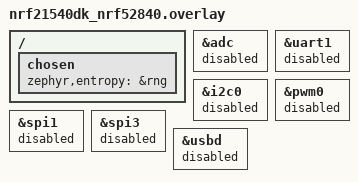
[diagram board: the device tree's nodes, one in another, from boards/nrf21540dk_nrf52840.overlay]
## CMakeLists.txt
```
#
# Copyright (c) 2021 Nordic Semiconductor ASA
#
# SPDX-License-Identifier: LicenseRef-Nordic-5-Clause
#

cmake_minimum_required(VERSION 3.20.0)

find_package(Zephyr REQUIRED HINTS $ENV{ZEPHYR_BASE})
project(matter-lock)

# Enable GNU STD support and initialize the Matter Data Model.
include(${ZEPHYR_CONNECTEDHOMEIP_MODULE_DIR}/config/nrfconnect/app/enable-gnu-std.cmake)
include(${ZEPHYR_CONNECTEDHOMEIP_MODULE_DIR}/src/app/chip_data_model.cmake)

# NORDIC SDK APP START

# Include all source files that are located in the Matter common directory.
include(${ZEPHYR_NRF_MODULE_DIR}/samples/matter/common/cmake/source_common.cmake)

target_include_directories(app PRIVATE
    src
    ${CONFIG_NCS_SAMPLE_MATTER_ZAP_FILES_PATH}
)

SET(access_srcs src/access/access_data_types.cpp
              src/access/access_manager_credentials.cpp
              src/access/access_manager_users.cpp
              src/access/access_manager.cpp
              src/access/access_storage.cpp
              )

if(CONFIG_LOCK_SCHEDULES)
    LIST(APPEND access_srcs src/access/access_manager_schedules.cpp)
endif()

target_sources(app PRIVATE
    src/app_task.cpp
    src/bolt_lock_manager.cpp
    src/main.cpp
    src/zcl_callbacks.cpp
    ${access_srcs}
)

if(CONFIG_THREAD_WIFI_SWITCHING)
    target_sources(app PRIVATE
        src/thread_wifi_switch.cpp
    )
endif()

chip_configure_data_model(app
    INCLUDE_SERVER
    BYPASS_IDL
    GEN_DIR ${CONFIG_NCS_SAMPLE_MATTER_ZAP_FILES_PATH}/zap-generated
    ZAP_FILE ${CMAKE_CURRENT_SOURCE_DIR}/${CONFIG_NCS_SAMPLE_MATTER_ZAP_FILES_PATH}/lock.zap
)
# NORDIC SDK APP END
```

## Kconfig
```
#
# Copyright (c) 2021 Nordic Semiconductor
#
# SPDX-License-Identifier: LicenseRef-Nordic-5-Clause
#

mainmenu "Matter Lock sample application"

config LOCK_MAX_NUM_USERS
	int "Maximum number of users supported by the lock"
	default 10

config LOCK_MAX_NUM_CREDENTIALS_PER_USER
	int "Maximum total number of credentials per one user supported by the lock"
	default 4

config LOCK_MAX_NUM_CREDENTIALS_PER_TYPE
	int "Maximum number of credentials of given type supported by the lock"
	default 15

config LOCK_MAX_CREDENTIAL_LENGTH
	int "Maximum length of the single credential supported by the lock"
	default 10

config LOCK_SCHEDULES
	bool "Support for WeekDay, YearDay and Holiday schedules in lock"
	help
	  This option adds support for an optional Timed Schedule Access Lock feature.
	  You can use Week Day, Year Day and Holiday schedules to restrict access for a
	  specific user for a defined time window. For example, use it to
	  give the user access only for three days in week.

if LOCK_SCHEDULES

config LOCK_MAX_WEEKDAY_SCHEDULES_PER_USER
	int "Maximum number of WeekDay schedules per one user supported by the lock"
	default 5

config LOCK_MAX_YEARDAY_SCHEDULES_PER_USER
	int "Maximum number of YearDay schedules per one user supported by the lock"
	default 5

config LOCK_MAX_HOLIDAY_SCHEDULES
	int "Maximum number of Holiday schedules supported by the lock"
	default 5

endif

config LOCK_ENABLE_DEBUG
	bool "Enable debug features to print users and credentials"
	depends on SHELL
	help
	  Debug features allows to checking and printing current users, their state, and
	  associated credentials. Use these with shell commands combinations to read saved credentials
	  or users, and manage them (add, clear, read).

if LOCK_ENABLE_DEBUG

config LOCK_PRINT_STORAGE_STATUS
	bool "Print storage status after each store call"
	help
	  Debug feature to print the debug-level log that contains information of the entry being stored
	  to persistent storage and how many bytes are left to store the new entry. It can be used to verify
	  whether credential, schedule or user entries are written properly to persistent storage.
	  This option should be disabled in production firmware
	  version.

# This should be deterined based on the maximum possible command length that depends on the LOCK_MAX_CREDENTIAL_LENGTH
config SHELL_CMD_BUFF_SIZE
	default 300

endif

config LOCK_LEAVE_FABRIC_CLEAR_CREDENTIAL
	bool "Clear all credentials assigned to given fabric index"
	default y
	help
	  This feature allows to remove all credentials which were created or modified
	  within the fabric which is being removed from the door lock.

config STATE_LEDS
	bool "Use LEDs to indicate the device state"
	default y
	help
	  Use LEDs to render the current state of the device such as the progress of commissioning of
	  the device into a network or the factory reset initiation. Note that setting this option to
	  'n' does not disable the LED indicating the state of the simulated bolt.

config THREAD_WIFI_SWITCHING
	bool "Switching between Thread and Wi-Fi"
	depends on SOC_SERIES_NRF53X
	depends on NET_L2_OPENTHREAD
	depends on CHIP_WIFI
	depends on !CHIP_FACTORY_RESET_ERASE_SETTINGS
	select EXPERIMENTAL
	help
	  Build the application with both Thread and Wi-Fi support and initialize
	  either transport based on the current configuration. A user can switch
	  between Thread and Wi-Fi by pressing and holding Button 3 for more than
	  10 seconds. During the switching, the device is automatically factory
	  reset and rebooted.

if THREAD_WIFI_SWITCHING

config THREAD_WIFI_SWITCHING_SHELL
	bool "Shell command for switching between Thread and Wi-Fi"
	default y if SHELL
	help
	  Add "switch_transport" shell command that initiates switching between
	  Thread and Wi-Fi transport for Matter protocol stack.

endif # THREAD_WIFI_SWITCHING

# Sample configuration used for Thread networking
if NET_L2_OPENTHREAD

choice OPENTHREAD_NORDIC_LIBRARY_CONFIGURATION
	default OPENTHREAD_NORDIC_LIBRARY_MTD
endchoice

choice OPENTHREAD_DEVICE_TYPE
	default OPENTHREAD_MTD
endchoice

config CHIP_ENABLE_ICD_SUPPORT
	default y

# Reduce Thread TX output power to 0 dBm for SED device
config OPENTHREAD_DEFAULT_TX_POWER
	int
	default 0

endif # NET_L2_OPENTHREAD

if CHIP_WIFI

config NRF_WIFI_LOW_POWER
	default y

endif # CHIP_WIFI

config NCS_SAMPLE_MATTER_PERSISTENT_STORAGE
	default y

# PSA SSF Crypto Client is not ready for the secure storage backend
if !PSA_SSF_CRYPTO_CLIENT

config NCS_SAMPLE_MATTER_SECURE_STORAGE_BACKEND
	default y if !CHIP_WIFI

config NCS_SAMPLE_MATTER_SETTINGS_STORAGE_BACKEND
	default n if !CHIP_WIFI

endif

# Increase the storage capacity if the schedules are enabled with secure storage
# This also implies increasing of the OT and Matter stacks because some operations
# performed during commissioning seem to allocate stack buffers based on the
# maximum possible secure asset size.
if LOCK_SCHEDULES && NCS_SAMPLE_MATTER_SECURE_STORAGE_BACKEND

config NCS_SAMPLE_MATTER_SECURE_STORAGE_MAX_ENTRY_NUMBER
	default 128

config TRUSTED_STORAGE_BACKEND_AEAD_MAX_DATA_SIZE
	default 3072

config OPENTHREAD_THREAD_STACK_SIZE
	default 5120

config CHIP_TASK_STACK_SIZE
	default 9216

endif

source "${ZEPHYR_CONNECTEDHOMEIP_MODULE_DIR}/config/nrfconnect/chip-module/Kconfig.features"
source "${ZEPHYR_CONNECTEDHOMEIP_MODULE_DIR}/config/nrfconnect/chip-module/Kconfig.defaults"
source "${ZEPHYR_NRF_MODULE_DIR}/samples/matter/common/src/Kconfig"
source "Kconfig.zephyr"
```

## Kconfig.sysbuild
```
#
# Copyright (c) 2023 Nordic Semiconductor ASA
#
# SPDX-License-Identifier: LicenseRef-Nordic-5-Clause
#

config WIFI_NRF70
	default y if BOARD_NRF7002DK

#### Radio core selection
config NRF_DEFAULT_IPC_RADIO
	default y

# Enable IEEE802.15.4 serialization to network core
# This config automatically pulls in the `overlay-802154.conf` in the ipc_radio image
config NETCORE_IPC_RADIO_IEEE802154
	default y if (SOC_SERIES_NRF53X || SOC_SERIES_NRF54HX) && !WIFI_NRF70

# Enable Bluetooth serialization to network core
# This config automatically pulls in the `overlay-bt_hci_ipc.conf` in the ipc_radio image
config NETCORE_IPC_RADIO_BT_HCI_IPC
	default y if (SOC_SERIES_NRF53X || SOC_SERIES_NRF54HX)

#### Bootloader
choice BOOTLOADER
	default BOOTLOADER_MCUBOOT if !BOARD_NRF21540DK && !SOC_SERIES_NRF54HX
endchoice

if BOOTLOADER_MCUBOOT

#### DFU multi-image support
config DFU_MULTI_IMAGE_PACKAGE_BUILD
	default y

config DFU_MULTI_IMAGE_PACKAGE_APP
	default y

config PM_EXTERNAL_FLASH_MCUBOOT_SECONDARY
	default y

#### DFU network core configuration
if SOC_SERIES_NRF53X

config MCUBOOT_UPDATEABLE_IMAGES
	default 2

choice MCUBOOT_MODE
	default MCUBOOT_MODE_OVERWRITE_ONLY
endchoice

choice BOOT_SIGNATURE_TYPE
	default BOOT_SIGNATURE_TYPE_RSA
endchoice

config SECURE_BOOT_NETCORE
	default y

config NETCORE_APP_UPDATE
	default y

config DFU_MULTI_IMAGE_PACKAGE_NET
	default y

endif # SOC_SERIES_NRF53X

if BOARD_NRF54L15DK_NRF54L15_CPUAPP_NS

# Disable checking the external drivers for NS build.
config PM_OVERRIDE_EXTERNAL_DRIVER_CHECK
	default y

# override the mcuboot pad size, because it is not set globally for NS build.
config PM_MCUBOOT_PAD
	default 0x800

endif # BOARD_NRF54L15DK_NRF54L15_CPUAPP_NS

endif # BOOTLOADER_MCUBOOT

if SOC_SERIES_NRF54HX

config SUIT_ENVELOPE
	default y

config SUIT_BUILD_FLASH_COMPANION
	default y

config SUIT_MULTI_IMAGE_PACKAGE_BUILD
	default y if MATTER_OTA

endif # SOC_SERIES_NRF54HX

#### Enable generating factory data
config MATTER_FACTORY_DATA_GENERATE
	default y if !BOARD_NRF21540DK

source "${ZEPHYR_BASE}/share/sysbuild/Kconfig"
```

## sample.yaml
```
sample:
  description: Matter Lock example
  name: Matter Lock
tests:
  sample.matter.lock.debug:
    sysbuild: true
    build_only: true
    integration_platforms:
      - nrf52840dk/nrf52840
      - nrf5340dk/nrf5340/cpuapp
      - nrf7002dk/nrf5340/cpuapp
      - nrf7002dk/nrf5340/cpuapp/nrf7001
      - nrf54l15dk/nrf54l15/cpuapp
      - nrf54l15dk/nrf54l15/cpuapp/ns
      - nrf54h20dk/nrf54h20/cpuapp
    platform_allow: nrf52840dk/nrf52840 nrf5340dk/nrf5340/cpuapp nrf7002dk/nrf5340/cpuapp
      nrf7002dk/nrf5340/cpuapp/nrf7001 nrf54l15dk/nrf54l15/cpuapp
      nrf54h20dk/nrf54h20/cpuapp nrf54l15dk/nrf54l15/cpuapp/ns
    tags: sysbuild ci_samples_matter
  sample.matter.lock.release:
    sysbuild: true
    build_only: true
    extra_args: FILE_SUFFIX=release
    integration_platforms:
      - nrf52840dk/nrf52840
      - nrf5340dk/nrf5340/cpuapp
      - nrf7002dk/nrf5340/cpuapp
      - nrf7002dk/nrf5340/cpuapp/nrf7001
      - nrf54l15dk/nrf54l15/cpuapp
      - nrf54h20dk/nrf54h20/cpuapp
    platform_allow: nrf52840dk/nrf52840 nrf5340dk/nrf5340/cpuapp nrf7002dk/nrf5340/cpuapp
      nrf7002dk/nrf5340/cpuapp/nrf7001 nrf54l15dk/nrf54l15/cpuapp
      nrf54h20dk/nrf54h20/cpuapp
    tags: sysbuild ci_samples_matter
  sample.matter.lock.lto:
    sysbuild: true
    build_only: true
    extra_args: CONFIG_LTO=y CONFIG_ISR_TABLES_LOCAL_DECLARATION=y
    integration_platforms:
      - nrf52840dk/nrf52840
      - nrf5340dk/nrf5340/cpuapp
      - nrf7002dk/nrf5340/cpuapp
      - nrf7002dk/nrf5340/cpuapp/nrf7001
      - nrf54l15dk/nrf54l15/cpuapp
    platform_allow: nrf52840dk/nrf52840 nrf5340dk/nrf5340/cpuapp nrf7002dk/nrf5340/cpuapp
      nrf7002dk/nrf5340/cpuapp/nrf7001 nrf54l15dk/nrf54l15/cpuapp
    tags: sysbuild ci_samples_matter
  sample.matter.lock.smp_dfu:
    sysbuild: true
    build_only: true
    extra_args: CONFIG_CHIP_DFU_OVER_BT_SMP=y
    integration_platforms:
      - nrf52840dk/nrf52840
      - nrf5340dk/nrf5340/cpuapp
      - nrf7002dk/nrf5340/cpuapp
      - nrf7002dk/nrf5340/cpuapp/nrf7001
      - nrf54l15dk/nrf54l15/cpuapp
    platform_allow: nrf52840dk/nrf52840 nrf5340dk/nrf5340/cpuapp nrf7002dk/nrf5340/cpuapp
      nrf7002dk/nrf5340/cpuapp/nrf7001 nrf54l15dk/nrf54l15/cpuapp
    tags: sysbuild ci_samples_matter
  sample.matter.lock.no_dfu.no_fd:
    sysbuild: true
    build_only: true
    extra_args: SB_CONFIG_MATTER_OTA=n
    integration_platforms:
      - nrf21540dk/nrf52840
    platform_allow: nrf21540dk/nrf52840
    tags: sysbuild ci_samples_matter
  sample.matter.lock.thread_wifi_switched.lto.smp_dfu:
    sysbuild: true
    build_only: true
    extra_args: lock_SHIELD=nrf7002ek
      FILE_SUFFIX=thread_wifi_switched SB_CONFIG_WIFI_PATCHES_EXT_FLASH_STORE=y
      SB_CONFIG_MCUBOOT_UPDATEABLE_IMAGES=3 CONFIG_CHIP_DFU_OVER_BT_SMP=y
      SB_CONFIG_WIFI_NRF70=y SB_CONFIG_DFU_MULTI_IMAGE_PACKAGE_WIFI_FW_PATCH=y
    integration_platforms:
      - nrf5340dk/nrf5340/cpuapp
    platform_allow: nrf5340dk/nrf5340/cpuapp
    tags: sysbuild ci_samples_matter
  sample.matter.lock.nus:
    sysbuild: true
    build_only: true
    extra_args: CONFIG_CHIP_NUS=y CONFIG_BT_FIXED_PASSKEY=y CONFIG_CHIP_NUS_FIXED_PASSKEY=112233
    integration_platforms:
      - nrf52840dk/nrf52840
      - nrf5340dk/nrf5340/cpuapp
    platform_allow: nrf52840dk/nrf52840 nrf5340dk/nrf5340/cpuapp nrf54l15dk/nrf54l15/cpuapp
    tags: sysbuild ci_samples_matter
  sample.matter.lock.release.nrf54l15.power_consumption:
    sysbuild: true
    build_only: true
    extra_args: FILE_SUFFIX=release CONFIG_NCS_SAMPLE_MATTER_LEDS=n
      CONFIG_CHIP_ENABLE_PAIRING_AUTOSTART=y CONFIG_NCS_SAMPLE_MATTER_WATCHDOG=n
    integration_platforms:
      - nrf54l15dk/nrf54l15/cpuapp
    platform_allow: nrf54l15dk/nrf54l15/cpuapp
    tags: sysbuild ci_samples_matter
```

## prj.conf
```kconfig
#
# Copyright (c) 2022 Nordic Semiconductor ASA
#
# SPDX-License-Identifier: LicenseRef-Nordic-5-Clause
#

# This sample uses Kconfig.defaults to set options common for all
# samples. This file should contain only options specific for this sample
# or overrides of default values.

# Enable CHIP
CONFIG_CHIP=y
CONFIG_CHIP_PROJECT_CONFIG="src/chip_project_config.h"
# 32774 == 0x8006 (example lock-app)
CONFIG_CHIP_DEVICE_PRODUCT_ID=32774
CONFIG_STD_CPP17=y

# Enable Matter extended announcement and increase duration to 1 hour.
CONFIG_CHIP_BLE_EXT_ADVERTISING=y
CONFIG_CHIP_BLE_ADVERTISING_DURATION=60

# Add support for LEDs and buttons on Nordic development kits
CONFIG_DK_LIBRARY=y

# Bluetooth Low Energy configuration
CONFIG_BT_DEVICE_NAME="MatterLock"

# Suspend devices when the CPU goes into sleep
CONFIG_PM_DEVICE=y

# Other settings
CONFIG_THREAD_NAME=y
CONFIG_MPU_STACK_GUARD=y
CONFIG_RESET_ON_FATAL_ERROR=n
CONFIG_CHIP_LIB_SHELL=y
CONFIG_NCS_SAMPLE_MATTER_TEST_SHELL=y

# Reduce application size
CONFIG_USE_SEGGER_RTT=n
CONFIG_MATTER_LOG_LEVEL_INF=y
CONFIG_CHIP_APP_LOG_LEVEL=3

# Enable Factory Data feature
CONFIG_CHIP_FACTORY_DATA=y
CONFIG_CHIP_FACTORY_DATA_BUILD=y
```

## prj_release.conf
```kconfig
#
# Copyright (c) 2022 Nordic Semiconductor ASA
#
# SPDX-License-Identifier: LicenseRef-Nordic-5-Clause
#

# This sample uses Kconfig.defaults to set options common for all
# samples. This file should contain only options specific for this sample
# or overrides of default values.

# Enable CHIP
CONFIG_CHIP=y
CONFIG_CHIP_PROJECT_CONFIG="src/chip_project_config.h"
# 32774 == 0x8006 (example lock-app)
CONFIG_CHIP_DEVICE_PRODUCT_ID=32774
CONFIG_STD_CPP17=y

# Enable Matter extended announcement and increase duration to 1 hour.
CONFIG_CHIP_BLE_EXT_ADVERTISING=y
CONFIG_CHIP_BLE_ADVERTISING_DURATION=60

# Add support for LEDs and buttons on Nordic development kits
CONFIG_DK_LIBRARY=y

# Bluetooth Low Energy configuration
CONFIG_BT_DEVICE_NAME="MatterLock"

# Suspend devices when the CPU goes into sleep
CONFIG_PM_DEVICE=y

# Enable system reset on fatal error
CONFIG_RESET_ON_FATAL_ERROR=y

# Try to disable unused RAM blocks to reduce power consumption
CONFIG_RAM_POWER_DOWN_LIBRARY=y

# Disable all debug features
CONFIG_USE_SEGGER_RTT=n
CONFIG_SHELL=n
CONFIG_OPENTHREAD_SHELL=n
CONFIG_CONSOLE=n
CONFIG_UART_CONSOLE=n
CONFIG_SERIAL=n
CONFIG_LOG=n
CONFIG_LOG_MODE_MINIMAL=n
CONFIG_ASSERT_VERBOSE=n
CONFIG_ASSERT_NO_FILE_INFO=y
CONFIG_PRINTK=n
CONFIG_PRINTK_SYNC=n
CONFIG_THREAD_NAME=n
CONFIG_BOOT_BANNER=n

# Enable Factory Data feature
CONFIG_CHIP_FACTORY_DATA=y
CONFIG_CHIP_FACTORY_DATA_BUILD=y

# Enable Watchdog
CONFIG_NCS_SAMPLE_MATTER_WATCHDOG=y
```

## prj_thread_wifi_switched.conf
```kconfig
#
# Copyright (c) 2022 Nordic Semiconductor ASA
#
# SPDX-License-Identifier: LicenseRef-Nordic-5-Clause
#

# This sample uses Kconfig.defaults to set options common for all
# samples. This file should contain only options specific for this sample
# or overrides of default values.

# Enable CHIP
CONFIG_CHIP=y
CONFIG_CHIP_PROJECT_CONFIG="src/chip_project_config.h"
# 32774 == 0x8006 (example lock-app)
CONFIG_CHIP_DEVICE_PRODUCT_ID=32774
CONFIG_STD_CPP17=y

# Enable Matter extended announcement and increase duration to 1 hour.
CONFIG_CHIP_BLE_EXT_ADVERTISING=y
CONFIG_CHIP_BLE_ADVERTISING_DURATION=60

# Add support for LEDs and buttons on Nordic development kits
CONFIG_DK_LIBRARY=y

# Bluetooth Low Energy configuration
CONFIG_BT_DEVICE_NAME="MatterLock"

# Other settings
CONFIG_MPU_STACK_GUARD=y
CONFIG_RESET_ON_FATAL_ERROR=n

# Enable switching between Thread and Wi-Fi variants
CONFIG_THREAD_WIFI_SWITCHING=y
CONFIG_THREAD_WIFI_SWITCHING_SHELL=y
CONFIG_CHIP_WIFI=y
CONFIG_NET_L2_OPENTHREAD=y
CONFIG_CHIP_FACTORY_RESET_ERASE_SETTINGS=n # Do not restore initial transport on factory reset

# Reduce application size
CONFIG_USE_SEGGER_RTT=n
CONFIG_WIFI_NM_WPA_SUPPLICANT_ADVANCED_FEATURES=n
CONFIG_CHIP_NFC_COMMISSIONING=n
CONFIG_MATTER_LOG_LEVEL_INF=y
CONFIG_CHIP_APP_LOG_LEVEL=3
CONFIG_THREAD_NAME=n
CONFIG_BOOT_BANNER=n

# Enable Factory Data feature
CONFIG_CHIP_FACTORY_DATA=y
CONFIG_CHIP_FACTORY_DATA_BUILD=y

# Enable LTO
CONFIG_LTO=y
CONFIG_ISR_TABLES_LOCAL_DECLARATION=y

# Enforce the use of mbedTLS crypto backend instead of PSA Crypto by
# building OpenThread from sources. Wi-Fi stack does not support PSA Crypto yet.
CONFIG_OPENTHREAD_SOURCES=y

# Do not enable RAM power-down library for nRF7002 DK due to incompatible WiFi configuration.
CONFIG_RAM_POWER_DOWN_LIBRARY=n
```

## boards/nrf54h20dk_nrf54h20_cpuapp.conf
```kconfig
#
# Copyright (c) 2024 Nordic Semiconductor ASA
#
# SPDX-License-Identifier: LicenseRef-Nordic-5-Clause
#

# Disable Oberon PSA crypto drivers
CONFIG_PSA_CRYPTO_DRIVER_OBERON=n

# Enable PSA crypto from SSF client
CONFIG_PSA_SSF_CRYPTO_CLIENT=y
CONFIG_SSF_PSA_CRYPTO_SERVICE_ENABLED=y

# Disable Data Cache
CONFIG_DCACHE=n

# Enable cache processing for application core.
# It will add the application firmware to the cache partition.
CONFIG_SUIT_DFU_CACHE_EXTRACT_IMAGE=y

# Set the ZMS sector count to match the settings partition size that is 32 kB for this application.
CONFIG_SETTINGS_ZMS_SECTOR_COUNT=8
# Workaround required as Zephyr L2 implies usage of NVS backend for settings.
# It should be removed once the proper fix will be applied in Zephyr.
CONFIG_NVS=n

# TODO: Enable factory data once it is available
CONFIG_CHIP_FACTORY_DATA=n
CONFIG_CHIP_CRYPTO_PSA_MIGRATE_DAC_PRIV_KEY=n

# TODO: Workaround to be removed once Zephyr's CONFIG_FPROTECT is supported on nRF54H20.
CONFIG_CHIP_FACTORY_DATA_WRITE_PROTECT=n

# Disable GPD
CONFIG_SOC_NRF54H20_GPD=n
```

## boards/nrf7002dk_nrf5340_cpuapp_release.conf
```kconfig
#
# Copyright (c) 2024 Nordic Semiconductor ASA
#
# SPDX-License-Identifier: LicenseRef-Nordic-5-Clause
#

# Do not enable RAM power-down library for nRF7002 DK due to incompatible WiFi configuration.
CONFIG_RAM_POWER_DOWN_LIBRARY=n

# Enable LTO to decrease the flash usage.
CONFIG_LTO=y
CONFIG_ISR_TABLES_LOCAL_DECLARATION=y
```

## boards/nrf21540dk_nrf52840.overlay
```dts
/* Copyright (c) 2021 Nordic Semiconductor ASA
 *
 * SPDX-License-Identifier: LicenseRef-Nordic-5-Clause
 */

/ {
	/*
	* In some default configurations within the nRF Connect SDK,
	* e.g. on nRF52840, the chosen zephyr,entropy node is &cryptocell.
	* This devicetree overlay ensures that default is overridden wherever it
	* is set, as this application uses the RNG node for entropy exclusively.
	*/
	chosen {
		zephyr,entropy = &rng;
	};
};

/* Disable unused peripherals to reduce power consumption */
&adc {
	status = "disabled";
};
&uart1 {
	status = "disabled";
};
&i2c0 {
	status = "disabled";
};
&pwm0 {
	status = "disabled";
};
&spi1 {
	status = "disabled";
};
&spi3 {
	status = "disabled";
};
&usbd {
	status = "disabled";
};
```

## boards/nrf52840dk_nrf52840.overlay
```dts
/* Copyright (c) 2021 Nordic Semiconductor ASA
 *
 * SPDX-License-Identifier: LicenseRef-Nordic-5-Clause
 */

/ {
	chosen {
		nordic,pm-ext-flash = &mx25r64;
	};

	/*
	* In some default configurations within the nRF Connect SDK,
	* e.g. on nRF52840, the chosen zephyr,entropy node is &cryptocell.
	* This devicetree overlay ensures that default is overridden wherever it
	* is set, as this application uses the RNG node for entropy exclusively.
	*/
	chosen {
		zephyr,entropy = &rng;
	};
};

/* Disable unused peripherals to reduce power consumption */
&adc {
	status = "disabled";
};
&uart1 {
	status = "disabled";
};
&i2c0 {
	status = "disabled";
};
&pwm0 {
	status = "disabled";
};
&spi1 {
	status = "disabled";
};
&spi3 {
	status = "disabled";
};
&usbd {
	status = "disabled";
};
```

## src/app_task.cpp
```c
/*
 * Copyright (c) 2021 Nordic Semiconductor ASA
 *
 * SPDX-License-Identifier: LicenseRef-Nordic-5-Clause
 */

#include "app_task.h"

#include "bolt_lock_manager.h"

#ifdef CONFIG_THREAD_WIFI_SWITCHING
#include "thread_wifi_switch.h"
#endif

#include "app/matter_init.h"
#include "app/task_executor.h"

#ifdef CONFIG_CHIP_NUS
#include "bt_nus/bt_nus_service.h"
#endif

#ifdef CONFIG_CHIP_OTA_REQUESTOR
#include "dfu/ota/ota_util.h"
#endif

#include <app-common/zap-generated/attributes/Accessors.h>
#include <app/clusters/door-lock-server/door-lock-server.h>
#include <app/clusters/identify-server/identify-server.h>
#include <app/server/OnboardingCodesUtil.h>
#include <platform/CHIPDeviceLayer.h>

#include <zephyr/logging/log.h>

LOG_MODULE_DECLARE(app, CONFIG_CHIP_APP_LOG_LEVEL);

using namespace ::chip;
using namespace ::chip::app;
using namespace ::chip::DeviceLayer;

namespace
{
constexpr EndpointId kLockEndpointId = 1;

#ifdef CONFIG_CHIP_NUS
constexpr uint16_t kAdvertisingIntervalMin = 400;
constexpr uint16_t kAdvertisingIntervalMax = 500;
constexpr uint8_t kLockNUSPriority = 2;
#endif

#ifdef CONFIG_THREAD_WIFI_SWITCHING
k_timer sSwitchTransportTimer;
constexpr uint32_t kSwitchTransportTimeout = 10000;
#endif

#define APPLICATION_BUTTON_MASK DK_BTN2_MSK
#define SWITCHING_BUTTON_MASK DK_BTN3_MSK
} /* namespace */

Identify sIdentify = { kLockEndpointId, AppTask::IdentifyStartHandler, AppTask::IdentifyStopHandler,
		       Clusters::Identify::IdentifyTypeEnum::kVisibleIndicator };

void AppTask::IdentifyStartHandler(Identify *)
{
	Nrf::PostTask(
		[] { Nrf::GetBoard().GetLED(Nrf::DeviceLeds::LED2).Blink(Nrf::LedConsts::kIdentifyBlinkRate_ms); });
}

void AppTask::IdentifyStopHandler(Identify *)
{
	Nrf::PostTask([] { Nrf::GetBoard().GetLED(Nrf::DeviceLeds::LED2).Set(BoltLockMgr().IsLocked()); });
}

void AppTask::ButtonEventHandler(Nrf::ButtonState state, Nrf::ButtonMask hasChanged)
{
	if ((APPLICATION_BUTTON_MASK & hasChanged) & state) {
		Nrf::PostTask([] { LockActionEventHandler(); });
	}

#ifdef CONFIG_THREAD_WIFI_SWITCHING
	if (SWITCHING_BUTTON_MASK & hasChanged) {
		SwitchButtonAction action =
			(SWITCHING_BUTTON_MASK & state) ? SwitchButtonAction::Pressed : SwitchButtonAction::Released;
		Nrf::PostTask([action] { SwitchTransportTriggerHandler(action); });
	}
#endif
}

void AppTask::LockActionEventHandler()
{
	if (BoltLockMgr().IsLocked()) {
		BoltLockMgr().Unlock(BoltLockManager::OperationSource::kButton);
	} else {
		BoltLockMgr().Lock(BoltLockManager::OperationSource::kButton);
	}
}

#ifdef CONFIG_THREAD_WIFI_SWITCHING
void AppTask::SwitchTransportEventHandler()
{
	LOG_INF("Switching to %s", ThreadWifiSwitch::IsThreadActive() ? "Wi-Fi" : "Thread");

	ThreadWifiSwitch::SwitchTransport();
}

void AppTask::SwitchTransportTimerTimeoutCallback(k_timer *timer)
{
	Nrf::PostTask([] { SwitchTransportEventHandler(); });
}

void AppTask::SwitchTransportTriggerHandler(const SwitchButtonAction &action)
{
	if (action == SwitchButtonAction::Pressed) {
		LOG_INF("Keep button pressed for %u ms to switch to %s", kSwitchTransportTimeout,
			ThreadWifiSwitch::IsThreadActive() ? "Wi-Fi" : "Thread");
		k_timer_start(&sSwitchTransportTimer, K_MSEC(kSwitchTransportTimeout), K_NO_WAIT);
	} else {
		LOG_INF("Switching to %s cancelled", ThreadWifiSwitch::IsThreadActive() ? "Wi-Fi" : "Thread");
		k_timer_stop(&sSwitchTransportTimer);
	}
}
#endif

void AppTask::LockStateChanged(BoltLockManager::State state, BoltLockManager::OperationSource source)
{
	switch (state) {
	case BoltLockManager::State::kLockingInitiated:
		LOG_INF("Lock action initiated");
		Nrf::GetBoard().GetLED(Nrf::DeviceLeds::LED2).Blink(50, 50);
#ifdef CONFIG_CHIP_NUS
		Nrf::GetNUSService().SendData("locking", sizeof("locking"));
#endif
		break;
	case BoltLockManager::State::kLockingCompleted:
		LOG_INF("Lock action completed");
		Nrf::GetBoard().GetLED(Nrf::DeviceLeds::LED2).Set(true);
#ifdef CONFIG_CHIP_NUS
		Nrf::GetNUSService().SendData("locked", sizeof("locked"));
#endif
		break;
	case BoltLockManager::State::kUnlockingInitiated:
		LOG_INF("Unlock action initiated");
		Nrf::GetBoard().GetLED(Nrf::DeviceLeds::LED2).Blink(50, 50);
#ifdef CONFIG_CHIP_NUS
		Nrf::GetNUSService().SendData("unlocking", sizeof("unlocking"));
#endif
		break;
	case BoltLockManager::State::kUnlockingCompleted:
		LOG_INF("Unlock action completed");
#ifdef CONFIG_CHIP_NUS
		Nrf::GetNUSService().SendData("unlocked", sizeof("unlocked"));
#endif
		Nrf::GetBoard().GetLED(Nrf::DeviceLeds::LED2).Set(false);
		break;
	}

	/* Handle changing attribute state in the application */
	Instance().UpdateClusterState(state, source);
}

void AppTask::UpdateClusterState(BoltLockManager::State state, BoltLockManager::OperationSource source)
{
	DlLockState newLockState;

	switch (state) {
	case BoltLockManager::State::kLockingCompleted:
		newLockState = DlLockState::kLocked;
		break;
	case BoltLockManager::State::kUnlockingCompleted:
		newLockState = DlLockState::kUnlocked;
		break;
	default:
		newLockState = DlLockState::kNotFullyLocked;
		break;
	}

	SystemLayer().ScheduleLambda([newLockState, source] {
		chip::app::DataModel::Nullable<chip::app::Clusters::DoorLock::DlLockState> currentLockState;
		chip::app::Clusters::DoorLock::Attributes::LockState::Get(kLockEndpointId, currentLockState);

		if (currentLockState.IsNull()) {
			/* Initialize lock state with start value, but not invoke lock/unlock. */
			chip::app::Clusters::DoorLock::Attributes::LockState::Set(kLockEndpointId, newLockState);
		} else {
			LOG_INF("Updating LockState attribute");

			if (!DoorLockServer::Instance().SetLockState(kLockEndpointId, newLockState, source)) {
				LOG_ERR("Failed to update LockState attribute");
			}
		}
	});
}

#ifdef CONFIG_CHIP_NUS
void AppTask::NUSLockCallback(void *context)
{
	LOG_DBG("Received LOCK command from NUS");
	if (BoltLockMgr().mState == BoltLockManager::State::kLockingCompleted ||
	    BoltLockMgr().mState == BoltLockManager::State::kLockingInitiated) {
		LOG_INF("Device is already locked");
	} else {
		Nrf::PostTask([] { LockActionEventHandler(); });
	}
}

void AppTask::NUSUnlockCallback(void *context)
{
	LOG_DBG("Received UNLOCK command from NUS");
	if (BoltLockMgr().mState == BoltLockManager::State::kUnlockingCompleted ||
	    BoltLockMgr().mState == BoltLockManager::State::kUnlockingInitiated) {
		LOG_INF("Device is already unlocked");
	} else {
		Nrf::PostTask([] { LockActionEventHandler(); });
	}
}
#endif

#ifdef CONFIG_NCS_SAMPLE_MATTER_TEST_EVENT_TRIGGERS
CHIP_ERROR AppTask::DoorLockJammedEventCallback(Nrf::Matter::TestEventTrigger::TriggerValue)
{
	VerifyOrReturnError(DoorLockServer::Instance().SendLockAlarmEvent(kLockEndpointId, AlarmCodeEnum::kLockJammed),
			    CHIP_ERROR_INTERNAL);
	LOG_ERR("Event Trigger: Doorlock jammed.");
	return CHIP_NO_ERROR;
}
#endif

CHIP_ERROR AppTask::Init()
{
	/* Initialize Matter stack */
#ifdef CONFIG_THREAD_WIFI_SWITCHING
	/* In the Thread/Wi-Fi switchable mode, it is the ThreadWifiSwitch module that owns the NetworkCommissioning
	   instances, so offload the initialization module from controlling that by explicitly setting the
	   mNetworkingInstance parameter to nullptr. Otherwise, the initialization module instantiates the
	   NetworkCommissioning object and handles it by default internally. */
	ReturnErrorOnFailure(Nrf::Matter::PrepareServer(Nrf::Matter::InitData{ .mNetworkingInstance = nullptr }));
#else
	ReturnErrorOnFailure(Nrf::Matter::PrepareServer());
#endif

	if (!Nrf::GetBoard().Init(ButtonEventHandler)) {
		LOG_ERR("User interface initialization failed.");
		return CHIP_ERROR_INCORRECT_STATE;
	}

	/* Register Matter event handler that controls the connectivity status LED based on the captured Matter network
	 * state. */
	ReturnErrorOnFailure(Nrf::Matter::RegisterEventHandler(Nrf::Board::DefaultMatterEventHandler, 0));

#ifdef CONFIG_THREAD_WIFI_SWITCHING
	CHIP_ERROR err = ThreadWifiSwitch::StartCurrentTransport();
	if (err != CHIP_NO_ERROR) {
		LOG_ERR("ThreadWifiSwitch::StartCurrentTransport() failed: %" CHIP_ERROR_FORMAT, err.Format());
		return err;
	}

	k_timer_init(&sSwitchTransportTimer, &AppTask::SwitchTransportTimerTimeoutCallback, nullptr);
#endif

#ifdef CONFIG_CHIP_NUS
	/* Initialize Nordic UART Service for Lock purposes */
	if (!Nrf::GetNUSService().Init(kLockNUSPriority, kAdvertisingIntervalMin, kAdvertisingIntervalMax)) {
		ChipLogError(Zcl, "Cannot initialize NUS service");
	}
	Nrf::GetNUSService().RegisterCommand("Lock", sizeof("Lock"), NUSLockCallback, nullptr);
	Nrf::GetNUSService().RegisterCommand("Unlock", sizeof("Unlock"), NUSUnlockCallback, nullptr);
	if (!Nrf::GetNUSService().StartServer()) {
		LOG_ERR("GetNUSService().StartServer() failed");
	}
#endif

	/* Initialize lock manager */
	BoltLockMgr().Init(LockStateChanged);

	/* Register Door Lock test event trigger */
#ifdef CONFIG_NCS_SAMPLE_MATTER_TEST_EVENT_TRIGGERS
	ReturnErrorOnFailure(Nrf::Matter::TestEventTrigger::Instance().RegisterTestEventTrigger(
		kDoorLockJammedEventTriggerId,
		Nrf::Matter::TestEventTrigger::EventTrigger{ 0, DoorLockJammedEventCallback }));
#endif

	return Nrf::Matter::StartServer();
}

CHIP_ERROR AppTask::StartApp()
{
	ReturnErrorOnFailure(Init());

	while (true) {
		Nrf::DispatchNextTask();
	}

	return CHIP_NO_ERROR;
}
```

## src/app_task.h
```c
/*
 * Copyright (c) 2021 Nordic Semiconductor ASA
 *
 * SPDX-License-Identifier: LicenseRef-Nordic-5-Clause
 */

#pragma once

#include "board/board.h"
#include "board/led_widget.h"
#include "bolt_lock_manager.h"

struct k_timer;
struct Identify;

#ifdef CONFIG_THREAD_WIFI_SWITCHING
enum class SwitchButtonAction : uint8_t { Pressed, Released };
#endif

#ifdef CONFIG_NCS_SAMPLE_MATTER_TEST_EVENT_TRIGGERS
#include "event_triggers/event_triggers.h"
#endif

class AppTask {
public:
	static AppTask &Instance()
	{
		static AppTask sAppTask;
		return sAppTask;
	};

	CHIP_ERROR StartApp();

	void UpdateClusterState(BoltLockManager::State state, BoltLockManager::OperationSource source);
	static void IdentifyStartHandler(Identify *);
	static void IdentifyStopHandler(Identify *);

private:
	CHIP_ERROR Init();

	static void LockActionEventHandler();
	static void ButtonEventHandler(Nrf::ButtonState state, Nrf::ButtonMask hasChanged);
	static void LockStateChanged(BoltLockManager::State state, BoltLockManager::OperationSource source);

#ifdef CONFIG_THREAD_WIFI_SWITCHING
	static void SwitchTransportEventHandler();
	static void SwitchTransportTimerTimeoutCallback(k_timer *timer);
	static void SwitchTransportTriggerHandler(const SwitchButtonAction &action);
#endif

#ifdef CONFIG_CHIP_NUS
	static void NUSLockCallback(void *context);
	static void NUSUnlockCallback(void *context);
#endif

#ifdef CONFIG_NCS_SAMPLE_MATTER_TEST_EVENT_TRIGGERS
	constexpr static Nrf::Matter::TestEventTrigger::EventTriggerId kDoorLockJammedEventTriggerId = 0xFFFF'FFFF'3277'4000;
	static CHIP_ERROR DoorLockJammedEventCallback(Nrf::Matter::TestEventTrigger::TriggerValue);
#endif
};
```

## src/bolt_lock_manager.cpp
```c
/*
 * Copyright (c) 2021 Nordic Semiconductor ASA
 *
 * SPDX-License-Identifier: LicenseRef-Nordic-5-Clause
 */

#include "bolt_lock_manager.h"
#include "app/task_executor.h"

#include "app_task.h"

using namespace chip;

BoltLockManager BoltLockManager::sLock;

void BoltLockManager::Init(StateChangeCallback callback)
{
	mStateChangeCallback = callback;

	k_timer_init(&mActuatorTimer, &BoltLockManager::ActuatorTimerEventHandler, nullptr);
	k_timer_user_data_set(&mActuatorTimer, this);

	AccessMgr::Instance().Init();

	/* Set the default state */
	Nrf::GetBoard().GetLED(Nrf::DeviceLeds::LED2).Set(IsLocked());
}

bool BoltLockManager::GetUser(uint16_t userIndex, EmberAfPluginDoorLockUserInfo &user)
{
	return AccessMgr::Instance().GetUserInfo(userIndex, user);
}

bool BoltLockManager::SetUser(uint16_t userIndex, FabricIndex creator, FabricIndex modifier, const CharSpan &userName,
			      uint32_t uniqueId, UserStatusEnum userStatus, UserTypeEnum userType,
			      CredentialRuleEnum credentialRule, const CredentialStruct *credentials,
			      size_t totalCredentials)
{
	return AccessMgr::Instance().SetUser(userIndex, creator, modifier, userName, uniqueId, userStatus, userType,
					      credentialRule, credentials, totalCredentials);
}

bool BoltLockManager::GetCredential(uint16_t credentialIndex, CredentialTypeEnum credentialType,
				    EmberAfPluginDoorLockCredentialInfo &credential)
{
	return AccessMgr::Instance().GetCredential(credentialIndex, credentialType, credential);
}

bool BoltLockManager::SetCredential(uint16_t credentialIndex, FabricIndex creator, FabricIndex modifier,
				    DlCredentialStatus credentialStatus, CredentialTypeEnum credentialType,
				    const ByteSpan &secret)
{
	return AccessMgr::Instance().SetCredential(credentialIndex, creator, modifier, credentialStatus,
						    credentialType, secret);
}

#ifdef CONFIG_LOCK_SCHEDULES

DlStatus BoltLockManager::GetWeekDaySchedule(uint8_t weekdayIndex, uint16_t userIndex,
					     EmberAfPluginDoorLockWeekDaySchedule &schedule)
{
	return AccessMgr::Instance().GetWeekDaySchedule(weekdayIndex, userIndex, schedule);
}

DlStatus BoltLockManager::SetWeekDaySchedule(uint8_t weekdayIndex, uint16_t userIndex, DlScheduleStatus status,
					     DaysMaskMap daysMask, uint8_t startHour, uint8_t startMinute,
					     uint8_t endHour, uint8_t endMinute)
{
	return AccessMgr::Instance().SetWeekDaySchedule(weekdayIndex, userIndex, status, daysMask, startHour,
							 startMinute, endHour, endMinute);
}

DlStatus BoltLockManager::GetYearDaySchedule(uint8_t yearDayIndex, uint16_t userIndex,
					     EmberAfPluginDoorLockYearDaySchedule &schedule)
{
	return AccessMgr::Instance().GetYearDaySchedule(yearDayIndex, userIndex, schedule);
}

DlStatus BoltLockManager::SetYearDaySchedule(uint8_t yeardayIndex, uint16_t userIndex, DlScheduleStatus status,
					     uint32_t localStartTime, uint32_t localEndTime)
{
	return AccessMgr::Instance().SetYearDaySchedule(yeardayIndex, userIndex, status, localStartTime, localEndTime);
}

DlStatus BoltLockManager::GetHolidaySchedule(uint8_t holidayIndex, EmberAfPluginDoorLockHolidaySchedule &schedule)
{
	return AccessMgr::Instance().GetHolidaySchedule(holidayIndex, schedule);
}

DlStatus BoltLockManager::SetHolidaySchedule(uint8_t holidayIndex, DlScheduleStatus status, uint32_t localStartTime,
					     uint32_t localEndTime, OperatingModeEnum operatingMode)
{
	return AccessMgr::Instance().SetHolidaySchedule(holidayIndex, status, localStartTime, localEndTime,
							 operatingMode);
}

#endif /* CONFIG_LOCK_SCHEDULES */


bool BoltLockManager::ValidatePIN(const Optional<ByteSpan> &pinCode, OperationErrorEnum &err)
{
	return AccessMgr::Instance().ValidatePIN(pinCode, err);
}

void BoltLockManager::SetRequirePIN(bool require)
{
	return AccessMgr::Instance().SetRequirePIN(require);
}
bool BoltLockManager::GetRequirePIN()
{
	return AccessMgr::Instance().GetRequirePIN();
}

void BoltLockManager::Lock(OperationSource source)
{
	VerifyOrReturn(mState != State::kLockingCompleted);
	SetState(State::kLockingInitiated, source);

	mActuatorOperationSource = source;
	k_timer_start(&mActuatorTimer, K_MSEC(kActuatorMovementTimeMs), K_NO_WAIT);
}

void BoltLockManager::Unlock(OperationSource source)
{
	VerifyOrReturn(mState != State::kUnlockingCompleted);
	SetState(State::kUnlockingInitiated, source);

	mActuatorOperationSource = source;
	k_timer_start(&mActuatorTimer, K_MSEC(kActuatorMovementTimeMs), K_NO_WAIT);
}

void BoltLockManager::ActuatorTimerEventHandler(k_timer *timer)
{
	/*
	 * The timer event handler is called in the context of the system clock ISR.
	 * Post an event to the application task queue to process the event in the
	 * context of the application thread.
	 */

	BoltLockManagerEvent event;
	event.manager = static_cast<BoltLockManager *>(k_timer_user_data_get(timer));
	Nrf::PostTask([event] { ActuatorAppEventHandler(event); });
}

void BoltLockManager::ActuatorAppEventHandler(const BoltLockManagerEvent &event)
{
	BoltLockManager *lock = reinterpret_cast<BoltLockManager *>(event.manager);

	switch (lock->mState) {
	case State::kLockingInitiated:
		lock->SetState(State::kLockingCompleted, lock->mActuatorOperationSource);
		break;
	case State::kUnlockingInitiated:
		lock->SetState(State::kUnlockingCompleted, lock->mActuatorOperationSource);
		break;
	default:
		break;
	}
}

void BoltLockManager::SetState(State state, OperationSource source)
{
	mState = state;

	if (mStateChangeCallback != nullptr) {
		mStateChangeCallback(state, source);
	}
}
```

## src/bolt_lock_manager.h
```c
/*
 * Copyright (c) 2021 Nordic Semiconductor ASA
 *
 * SPDX-License-Identifier: LicenseRef-Nordic-5-Clause
 */

#pragma once

#include "access/access_manager.h"

#include <app/clusters/door-lock-server/door-lock-server.h>
#include <lib/core/ClusterEnums.h>

#include <zephyr/kernel.h>

#include <cstdint>

struct BoltLockManagerEvent;

class BoltLockManager {
public:
	static constexpr size_t kMaxCredentialLength = 128;

	enum class State : uint8_t {
		kLockingInitiated = 0,
		kLockingCompleted,
		kUnlockingInitiated,
		kUnlockingCompleted,
	};

	struct UserData {
		char mName[DOOR_LOCK_USER_NAME_BUFFER_SIZE];
		CredentialStruct mCredentials[CONFIG_LOCK_MAX_NUM_CREDENTIALS_PER_USER];
	};

	struct CredentialData {
		chip::Platform::ScopedMemoryBuffer<uint8_t> mSecret;
	};

	using OperationSource = chip::app::Clusters::DoorLock::OperationSourceEnum;
	using StateChangeCallback = void (*)(State, OperationSource);

	static constexpr uint32_t kActuatorMovementTimeMs = 2000;

	void Init(StateChangeCallback callback);

	State GetState() const { return mState; }
	bool IsLocked() const { return mState == State::kLockingCompleted; }

	bool GetUser(uint16_t userIndex, EmberAfPluginDoorLockUserInfo &user);
	bool SetUser(uint16_t userIndex, chip::FabricIndex creator, chip::FabricIndex modifier,
		     const chip::CharSpan &userName, uint32_t uniqueId, UserStatusEnum userStatus,
		     UserTypeEnum userType, CredentialRuleEnum credentialRule, const CredentialStruct *credentials,
		     size_t totalCredentials);

	bool GetCredential(uint16_t credentialIndex, CredentialTypeEnum credentialType,
			   EmberAfPluginDoorLockCredentialInfo &credential);
	bool SetCredential(uint16_t credentialIndex, chip::FabricIndex creator, chip::FabricIndex modifier,
			   DlCredentialStatus credentialStatus, CredentialTypeEnum credentialType,
			   const chip::ByteSpan &secret);

#ifdef CONFIG_LOCK_SCHEDULES
	DlStatus GetWeekDaySchedule(uint8_t weekdayIndex, uint16_t userIndex,
				    EmberAfPluginDoorLockWeekDaySchedule &schedule);
	DlStatus SetWeekDaySchedule(uint8_t weekdayIndex, uint16_t userIndex, DlScheduleStatus status,
				    DaysMaskMap daysMask, uint8_t startHour, uint8_t startMinute, uint8_t endHour,
				    uint8_t endMinute);
	DlStatus GetYearDaySchedule(uint8_t yearDayIndex, uint16_t userIndex,
				    EmberAfPluginDoorLockYearDaySchedule &schedule);
	DlStatus SetYearDaySchedule(uint8_t yearDayIndex, uint16_t userIndex, DlScheduleStatus status,
				    uint32_t localStartTime, uint32_t localEndTime);
	DlStatus GetHolidaySchedule(uint8_t holidayIndex, EmberAfPluginDoorLockHolidaySchedule &schedule);
	DlStatus SetHolidaySchedule(uint8_t holidayIndex, DlScheduleStatus status, uint32_t localStartTime,
				    uint32_t localEndTime, OperatingModeEnum operatingMode);
#endif /* CONFIG_LOCK_SCHEDULES */

	bool ValidatePIN(const Optional<chip::ByteSpan> &pinCode, OperationErrorEnum &err);

	void Lock(OperationSource source);
	void Unlock(OperationSource source);

	void SetRequirePIN(bool require);
	bool GetRequirePIN();

private:
	using AccessMgr = AccessManager<DoorLockData::PIN>;
	friend class AppTask;

	void SetState(State state, OperationSource source);

	static void ActuatorTimerEventHandler(k_timer *timer);
	static void ActuatorAppEventHandler(const BoltLockManagerEvent &event);
	friend BoltLockManager &BoltLockMgr();

	State mState = State::kLockingCompleted;
	StateChangeCallback mStateChangeCallback = nullptr;
	OperationSource mActuatorOperationSource = OperationSource::kButton;
	k_timer mActuatorTimer = {};

	static BoltLockManager sLock;
};

inline BoltLockManager &BoltLockMgr()
{
	return BoltLockManager::sLock;
}

struct BoltLockManagerEvent {
	BoltLockManager *manager;
};
```

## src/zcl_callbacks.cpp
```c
/*
 * Copyright (c) 2021 Nordic Semiconductor ASA
 *
 * SPDX-License-Identifier: LicenseRef-Nordic-5-Clause
 */

#include "app_task.h"
#include "bolt_lock_manager.h"

#include <app-common/zap-generated/attributes/Accessors.h>
#include <app-common/zap-generated/ids/Clusters.h>
#include <app/ConcreteAttributePath.h>
#include <app/clusters/door-lock-server/door-lock-server.h>
#include <app/data-model/Nullable.h>
#include <lib/core/DataModelTypes.h>
#include <lib/support/CodeUtils.h>

using namespace ::chip;
using namespace ::chip::app::Clusters;
using namespace ::chip::app::Clusters::DoorLock;
using ::chip::app::DataModel::Nullable;

void MatterPostAttributeChangeCallback(const chip::app::ConcreteAttributePath &attributePath, uint8_t type,
				       uint16_t size, uint8_t *value)
{
	VerifyOrReturn(attributePath.mClusterId == DoorLock::Id);

	if (attributePath.mAttributeId == DoorLock::Attributes::LockState::Id) {
		/* Post events only if current lock state is different than given */
		switch (*value) {
		case to_underlying(DlLockState::kLocked):
			BoltLockMgr().Lock(BoltLockManager::OperationSource::kRemote);
			break;
		case to_underlying(DlLockState::kUnlocked):
			BoltLockMgr().Unlock(BoltLockManager::OperationSource::kRemote);
			break;
		default:
			break;
		}
	} else if (attributePath.mAttributeId == DoorLock::Attributes::RequirePINforRemoteOperation::Id) {
		BoltLockMgr().SetRequirePIN(*value);
	}
}

bool emberAfPluginDoorLockGetUser(EndpointId endpointId, uint16_t userIndex, EmberAfPluginDoorLockUserInfo &user)
{
	return BoltLockMgr().GetUser(userIndex, user);
}

bool emberAfPluginDoorLockSetUser(EndpointId endpointId, uint16_t userIndex, FabricIndex creator, FabricIndex modifier,
				  const CharSpan &userName, uint32_t uniqueId, UserStatusEnum userStatus,
				  UserTypeEnum userType, CredentialRuleEnum credentialRule,
				  const CredentialStruct *credentials, size_t totalCredentials)
{
	return BoltLockMgr().SetUser(userIndex, creator, modifier, userName, uniqueId, userStatus, userType,
				     credentialRule, credentials, totalCredentials);
}

bool emberAfPluginDoorLockGetCredential(EndpointId endpointId, uint16_t credentialIndex,
					CredentialTypeEnum credentialType,
					EmberAfPluginDoorLockCredentialInfo &credential)
{
	return BoltLockMgr().GetCredential(credentialIndex, credentialType, credential);
}

bool emberAfPluginDoorLockSetCredential(EndpointId endpointId, uint16_t credentialIndex, FabricIndex creator,
					FabricIndex modifier, DlCredentialStatus credentialStatus,
					CredentialTypeEnum credentialType, const ByteSpan &secret)
{
	return BoltLockMgr().SetCredential(credentialIndex, creator, modifier, credentialStatus, credentialType,
					   secret);
}

bool emberAfPluginDoorLockOnDoorLockCommand(EndpointId endpointId, const Nullable<chip::FabricIndex> &fabricIdx,
					    const Nullable<chip::NodeId> &nodeId, const Optional<ByteSpan> &pinCode,
					    OperationErrorEnum &err)
{
	bool result = BoltLockMgr().ValidatePIN(pinCode, err);

	/* Handle changing attribute state on command reception */
	if (result) {
		BoltLockMgr().Lock(BoltLockManager::OperationSource::kRemote);
	}

	return result;
}

bool emberAfPluginDoorLockOnDoorUnlockCommand(EndpointId endpointId, const Nullable<chip::FabricIndex> &fabricIdx,
					      const Nullable<chip::NodeId> &nodeId, const Optional<ByteSpan> &pinCode,
					      OperationErrorEnum &err)
{
	bool result = BoltLockMgr().ValidatePIN(pinCode, err);

	/* Handle changing attribute state on command reception */
	if (result) {
		BoltLockMgr().Unlock(BoltLockManager::OperationSource::kRemote);
	}

	return result;
}

void emberAfDoorLockClusterInitCallback(EndpointId endpoint)
{
	DoorLockServer::Instance().InitServer(endpoint);

	const auto logOnFailure = [](Protocols::InteractionModel::Status status, const char *attributeName) {
		if (status != Protocols::InteractionModel::Status::Success) {
			ChipLogError(Zcl, "Failed to set DoorLock %s: %x", attributeName, to_underlying(status));
		}
	};

	logOnFailure(DoorLock::Attributes::LockType::Set(endpoint, DlLockType::kDeadBolt), "type");
	logOnFailure(DoorLock::Attributes::NumberOfTotalUsersSupported::Set(endpoint, CONFIG_LOCK_MAX_NUM_USERS),
		     "number of users");
	logOnFailure(DoorLock::Attributes::NumberOfPINUsersSupported::Set(endpoint,
									  CONFIG_LOCK_MAX_NUM_CREDENTIALS_PER_TYPE),
		     "number of PIN users");
	logOnFailure(DoorLock::Attributes::NumberOfRFIDUsersSupported::Set(endpoint, 0), "number of RFID users");
	logOnFailure(DoorLock::Attributes::NumberOfCredentialsSupportedPerUser::Set(
			     endpoint, CONFIG_LOCK_MAX_NUM_CREDENTIALS_PER_USER),
		     "number of credentials per user");
	logOnFailure(DoorLock::Attributes::RequirePINforRemoteOperation::Set(endpoint, BoltLockMgr().GetRequirePIN()),
		     "require PIN code for the remote operation");

#ifdef CONFIG_LOCK_SCHEDULES
	logOnFailure(DoorLock::Attributes::NumberOfWeekDaySchedulesSupportedPerUser::Set(
			     endpoint, CONFIG_LOCK_MAX_WEEKDAY_SCHEDULES_PER_USER),
		     "number of WeekDay schedules per user");
	logOnFailure(DoorLock::Attributes::NumberOfYearDaySchedulesSupportedPerUser::Set(
			     endpoint, CONFIG_LOCK_MAX_YEARDAY_SCHEDULES_PER_USER),
		     "number of YearDay schedules per user");
	logOnFailure(DoorLock::Attributes::NumberOfHolidaySchedulesSupported::Set(endpoint,
										  CONFIG_LOCK_MAX_HOLIDAY_SCHEDULES),
		     "number of holiday schedules");
#endif /* CONFIG_LOCK_SCHEDULES */

	AppTask::Instance().UpdateClusterState(BoltLockMgr().GetState(),
					       BoltLockManager::OperationSource::kUnspecified);
}

#ifdef CONFIG_LOCK_SCHEDULES

DlStatus emberAfPluginDoorLockGetSchedule(chip::EndpointId endpointId, uint8_t weekdayIndex, uint16_t userIndex,
					  EmberAfPluginDoorLockWeekDaySchedule &schedule)
{
	return BoltLockMgr().GetWeekDaySchedule(weekdayIndex, userIndex, schedule);
}

DlStatus emberAfPluginDoorLockGetSchedule(chip::EndpointId endpointId, uint8_t yearDayIndex, uint16_t userIndex,
					  EmberAfPluginDoorLockYearDaySchedule &schedule)
{
	return BoltLockMgr().GetYearDaySchedule(yearDayIndex, userIndex, schedule);
}

DlStatus emberAfPluginDoorLockGetSchedule(chip::EndpointId endpointId, uint8_t holidayIndex,
					  EmberAfPluginDoorLockHolidaySchedule &holidaySchedule)
{
	return BoltLockMgr().GetHolidaySchedule(holidayIndex, holidaySchedule);
}

DlStatus emberAfPluginDoorLockSetSchedule(chip::EndpointId endpointId, uint8_t weekdayIndex, uint16_t userIndex,
					  DlScheduleStatus status, DaysMaskMap daysMask, uint8_t startHour,
					  uint8_t startMinute, uint8_t endHour, uint8_t endMinute)
{
	return BoltLockMgr().SetWeekDaySchedule(weekdayIndex, userIndex, status, daysMask, startHour, startMinute,
						endHour, endMinute);
}

DlStatus emberAfPluginDoorLockSetSchedule(chip::EndpointId endpointId, uint8_t yearDayIndex, uint16_t userIndex,
					  DlScheduleStatus status, uint32_t localStartTime, uint32_t localEndTime)
{
	return BoltLockMgr().SetYearDaySchedule(yearDayIndex, userIndex, status, localStartTime, localEndTime);
}

DlStatus emberAfPluginDoorLockSetSchedule(chip::EndpointId endpointId, uint8_t holidayIndex, DlScheduleStatus status,
					  uint32_t localStartTime, uint32_t localEndTime,
					  OperatingModeEnum operatingMode)
{
	return BoltLockMgr().SetHolidaySchedule(holidayIndex, status, localStartTime, localEndTime, operatingMode);
}

#endif /* CONFIG_LOCK_SCHEDULES */
```
